# STM32F101xx register map
File version: 1.1
CPU: 
Registers are 32-bit, read-write, reset 0x0 unless marked. A register's access mark holds for its fields unless they carry their own. Offsets are from the block's base; [hi:lo] are bit positions.

## TIM6 — Basic timer
Base 0x40001000
Same registers: TIM7 0x40001400
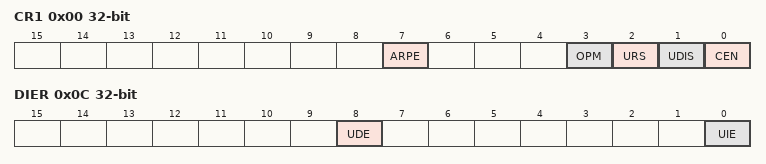
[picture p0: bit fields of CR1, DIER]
0x00 CR1 — control register 1
  [7] ARPE — Auto-reload preload enable
  [3] OPM — One-pulse mode
  [2] URS — Update request source
  [1] UDIS — Update disable
  [0] CEN — Counter enable
0x04 CR2 — control register 2
  [6:4] MMS — Master mode selection
0x0C DIER — DMA/Interrupt enable register
  [8] UDE — Update DMA request enable
  [0] UIE — Update interrupt enable
0x10 SR — status register
  [0] UIF — Update interrupt flag
0x14 EGR wo — event generation register
  [0] UG — Update generation
0x24 CNT — counter
  [15:0] CNT — Low counter value
0x28 PSC — prescaler
  [15:0] PSC — Prescaler value
0x2C ARR — auto-reload register
  [15:0] ARR — Low Auto-reload value

## I2C1 — Inter integrated circuit
Base 0x40005400
Same registers: I2C2 0x40005800
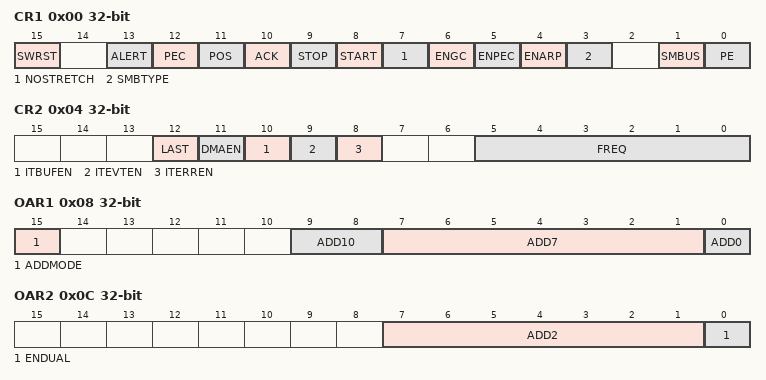
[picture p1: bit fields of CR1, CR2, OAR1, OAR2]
0x00 CR1 — Control register 1
  [15] SWRST — Software reset
  [13] ALERT — SMBus alert
  [12] PEC — Packet error checking
  [11] POS — Acknowledge/PEC Position (for data reception)
  [10] ACK — Acknowledge enable
  [9] STOP — Stop generation
  [8] START — Start generation
  [7] NOSTRETCH — Clock stretching disable (Slave mode)
  [6] ENGC — General call enable
  [5] ENPEC — PEC enable
  [4] ENARP — ARP enable
  [3] SMBTYPE — SMBus type
  [1] SMBUS — SMBus mode
  [0] PE — Peripheral enable
0x04 CR2 — Control register 2
  [12] LAST — DMA last transfer
  [11] DMAEN — DMA requests enable
  [10] ITBUFEN — Buffer interrupt enable
  [9] ITEVTEN — Event interrupt enable
  [8] ITERREN — Error interrupt enable
  [5:0] FREQ — Peripheral clock frequency
0x08 OAR1 — Own address register 1
  [15] ADDMODE — Addressing mode (slave mode)
  [9:8] ADD10 — Interface address
  [7:1] ADD7 — Interface address
  [0] ADD0 — Interface address
0x0C OAR2 — Own address register 2
  [7:1] ADD2 — Interface address
  [0] ENDUAL — Dual addressing mode enable
0x10 DR — Data register
  [7:0] DR — 8-bit data register
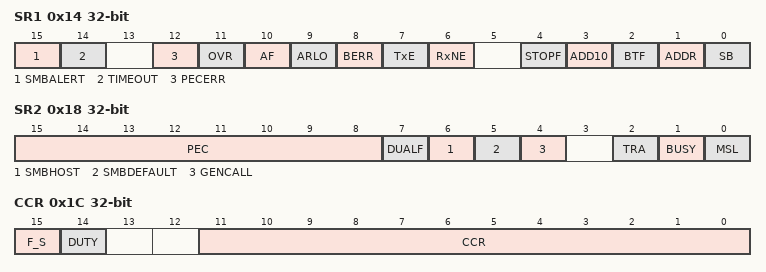
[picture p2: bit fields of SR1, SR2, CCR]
0x14 SR1 access per field — Status register 1
  [15] SMBALERT rw — SMBus alert
  [14] TIMEOUT rw — Timeout or Tlow error
  [12] PECERR rw — PEC Error in reception
  [11] OVR rw — Overrun/Underrun
  [10] AF rw — Acknowledge failure
  [9] ARLO rw — Arbitration lost (master mode)
  [8] BERR rw — Bus error
  [7] TxE ro — Data register empty (transmitters)
  [6] RxNE ro — Data register not empty (receivers)
  [4] STOPF ro — Stop detection (slave mode)
  [3] ADD10 ro — 10-bit header sent (Master mode)
  [2] BTF ro — Byte transfer finished
  [1] ADDR ro — Address sent (master mode)/matched (slave mode)
  [0] SB ro — Start bit (Master mode)
0x18 SR2 ro — Status register 2
  [15:8] PEC — acket error checking register
  [7] DUALF — Dual flag (Slave mode)
  [6] SMBHOST — SMBus host header (Slave mode)
  [5] SMBDEFAULT — SMBus device default address (Slave mode)
  [4] GENCALL — General call address (Slave mode)
  [2] TRA — Transmitter/receiver
  [1] BUSY — Bus busy
  [0] MSL — Master/slave
0x1C CCR — Clock control register
  [15] F_S — I2C master mode selection
  [14] DUTY — Fast mode duty cycle
  [11:0] CCR — Clock control register in Fast/Standard mode (Master mode)
0x20 TRISE reset 0x2
  [5:0] TRISE — Maximum rise time in Fast/Standard mode (Master mode)

## SPI1 — Serial peripheral interface
Base 0x40013000
Same registers: SPI2 0x40003800, SPI3 0x40003C00
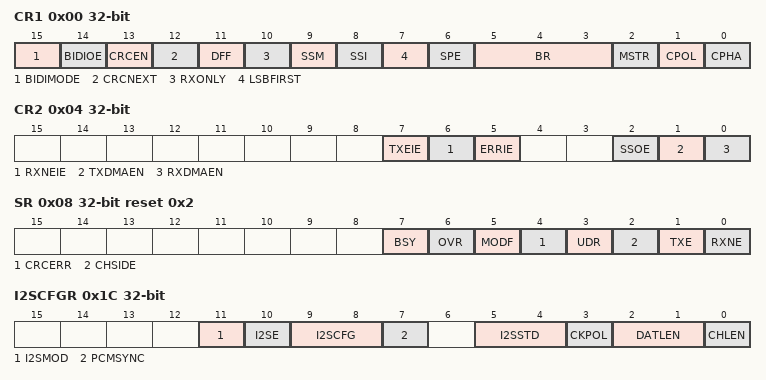
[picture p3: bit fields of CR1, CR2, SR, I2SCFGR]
0x00 CR1 — control register 1
  [15] BIDIMODE — Bidirectional data mode enable
  [14] BIDIOE — Output enable in bidirectional mode
  [13] CRCEN — Hardware CRC calculation enable
  [12] CRCNEXT — CRC transfer next
  [11] DFF — Data frame format
  [10] RXONLY — Receive only
  [9] SSM — Software slave management
  [8] SSI — Internal slave select
  [7] LSBFIRST — Frame format
  [6] SPE — SPI enable
  [5:3] BR — Baud rate control
  [2] MSTR — Master selection
  [1] CPOL — Clock polarity
  [0] CPHA — Clock phase
0x04 CR2 — control register 2
  [7] TXEIE — Tx buffer empty interrupt enable
  [6] RXNEIE — RX buffer not empty interrupt enable
  [5] ERRIE — Error interrupt enable
  [2] SSOE — SS output enable
  [1] TXDMAEN — Tx buffer DMA enable
  [0] RXDMAEN — Rx buffer DMA enable
0x08 SR access per field reset 0x2 — status register
  [7] BSY ro — Busy flag
  [6] OVR ro — Overrun flag
  [5] MODF ro — Mode fault
  [4] CRCERR rw — CRC error flag
  [3] UDR ro — Underrun flag
  [2] CHSIDE ro — Channel side
  [1] TXE ro — Transmit buffer empty
  [0] RXNE ro — Receive buffer not empty
0x0C DR — data register
  [15:0] DR — Data register
0x10 CRCPR reset 0x7 — CRC polynomial register
  [15:0] CRCPOLY
0x14 RXCRCR ro — RX CRC register
  [15:0] RxCRC
0x18 TXCRCR ro — TX CRC register
  [15:0] TxCRC
0x1C I2SCFGR — I2S configuration register
  [11] I2SMOD — I2S mode selection
  [10] I2SE — I2S Enable
  [9:8] I2SCFG — I2S configuration mode
  [7] PCMSYNC — PCM frame synchronization
  [5:4] I2SSTD — I2S standard selection
  [3] CKPOL — Steady state clock polarity
  [2:1] DATLEN — Data length to be transferred
  [0] CHLEN — Channel length (number of bits per audio channel)
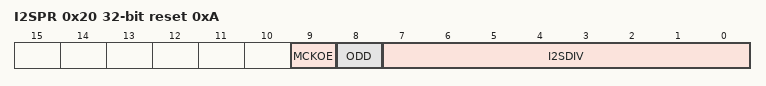
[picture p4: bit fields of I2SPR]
0x20 I2SPR reset 0xA — I2S prescaler register
  [9] MCKOE — Master clock output enable
  [8] ODD — Odd factor for the prescaler
  [7:0] I2SDIV — I2S Linear prescaler
